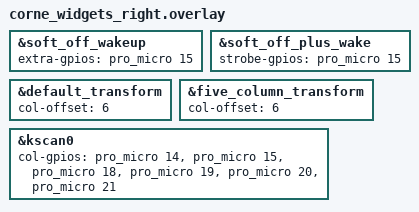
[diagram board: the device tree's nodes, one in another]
/*
 * Copyright (c) 2020 Pete Johanson
 *
 * SPDX-License-Identifier: MIT
 */

#include "corne_widgets.dtsi"

&soft_off_wakeup {
    extra-gpios = <&pro_micro 15 GPIO_ACTIVE_HIGH>;
};

&soft_off_plus_wake {
    strobe-gpios = <&pro_micro 15 GPIO_ACTIVE_HIGH>;
};

&default_transform {
    col-offset = <6>;
};

&five_column_transform {
    col-offset = <6>;
};

&kscan0 {
    col-gpios
        = <&pro_micro 14 GPIO_ACTIVE_HIGH>
        , <&pro_micro 15 GPIO_ACTIVE_HIGH>
        , <&pro_micro 18 GPIO_ACTIVE_HIGH>
        , <&pro_micro 19 GPIO_ACTIVE_HIGH>
        , <&pro_micro 20 GPIO_ACTIVE_HIGH>
        , <&pro_micro 21 GPIO_ACTIVE_HIGH>
        ;
};
